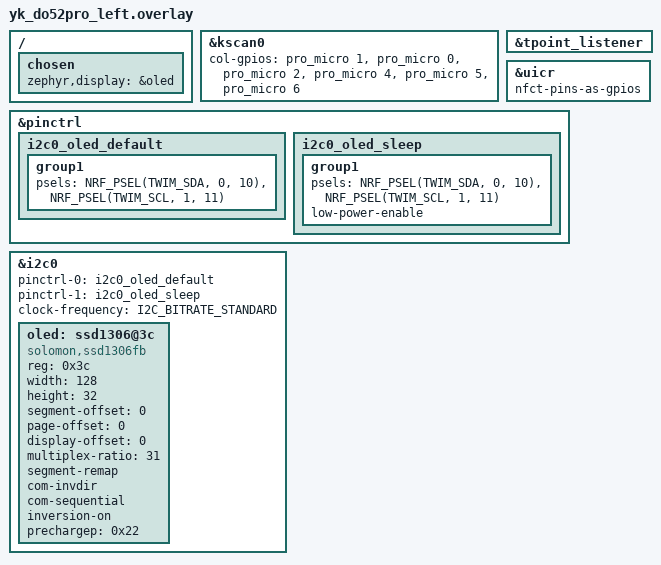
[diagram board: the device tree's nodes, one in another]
/*
 * Copyright (c) 2020 Pete Johanson
 *
 * SPDX-License-Identifier: MIT
 */

#include "yk_do52pro.dtsi"

&kscan0 {
    col-gpios
        = <&pro_micro 1 GPIO_ACTIVE_HIGH>
        , <&pro_micro 0 GPIO_ACTIVE_HIGH>
        , <&pro_micro 2 GPIO_ACTIVE_HIGH>
        , <&pro_micro 4 GPIO_ACTIVE_HIGH>
        , <&pro_micro 5 GPIO_ACTIVE_HIGH>
        , <&pro_micro 6 GPIO_ACTIVE_HIGH>
        ;
};

&tpoint_listener {
     status = "okay";
 };

/ {
    chosen {
        zephyr,display = &oled;
    };
};

// P0.10 is an NFC pin on nRF52840
&uicr {
    nfct-pins-as-gpios;
};

&pinctrl {
    i2c0_oled_default: i2c0_oled_default {
        group1 {
            psels = <NRF_PSEL(TWIM_SDA, 0, 10)>,
                    <NRF_PSEL(TWIM_SCL, 1, 11)>;
        };
    };

    i2c0_oled_sleep: i2c0_oled_sleep {
        group1 {
            psels = <NRF_PSEL(TWIM_SDA, 0, 10)>,
                    <NRF_PSEL(TWIM_SCL, 1, 11)>;
            low-power-enable;
        };
    };
};

&i2c0 {
    status = "okay";
    pinctrl-0 = <&i2c0_oled_default>;
    pinctrl-1 = <&i2c0_oled_sleep>;
    pinctrl-names = "default", "sleep";
    clock-frequency = <I2C_BITRATE_STANDARD>;

    oled: ssd1306@3c {
        compatible = "solomon,ssd1306fb";
        reg = <0x3c>;
        width = <128>;
        height = <32>;
        segment-offset = <0>;
        page-offset = <0>;
        display-offset = <0>;
        multiplex-ratio = <31>;
        segment-remap;
        com-invdir;
        com-sequential;
        inversion-on;
        prechargep = <0x22>;
    };
};

